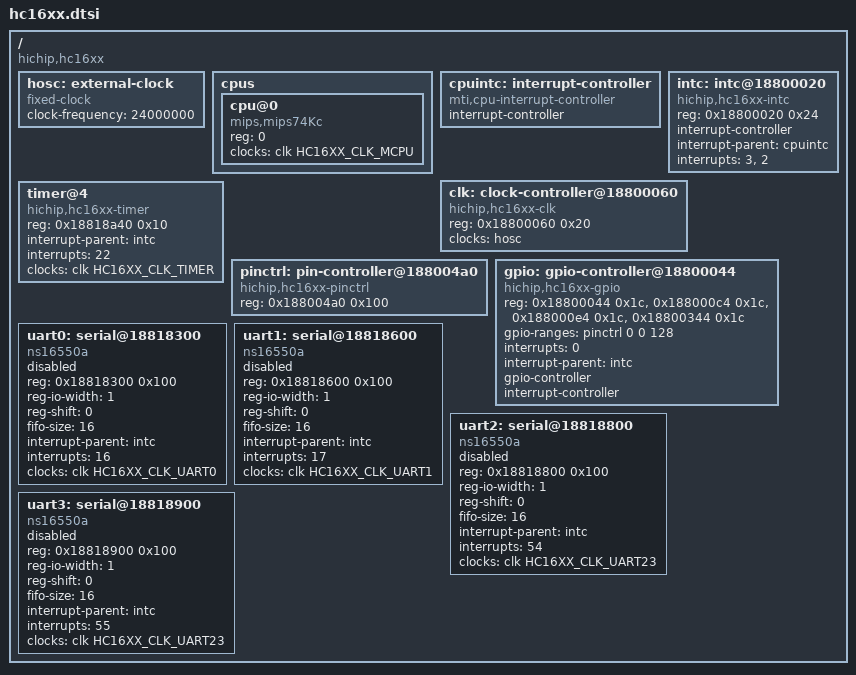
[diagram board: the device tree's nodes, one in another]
// SPDX-License-Identifier: (GPL-2.0-only OR BSD-2-Clause)
/dts-v1/;

#include <dt-bindings/clock/hichip,hc16xx-clock.h>

/ {
	compatible = "hichip,hc16xx";
	#address-cells = <1>;
	#size-cells = <1>;

	hosc: external-clock {
		compatible = "fixed-clock";
		#clock-cells = <0>;
		clock-frequency = <24000000>;  /* 24 MHz, typical */
	};

	cpus: cpus {
		#address-cells = <1>;
		#size-cells = <0>;

		cpu@0 {
			device_type = "cpu";
			compatible = "mips,mips74Kc";
			reg = <0>;

			clocks = <&clk HC16XX_CLK_MCPU>;
			clock-names = "cpu";
		};
	};

	cpuintc: interrupt-controller {
		compatible = "mti,cpu-interrupt-controller";
		interrupt-controller;
		#address-cells = <0>;
		#interrupt-cells = <1>;
	};

	intc: intc@18800020 {
		compatible="hichip,hc16xx-intc";
		reg = <0x18800020 0x24>;

		interrupt-controller;
		#interrupt-cells = <1>;

		interrupt-parent = <&cpuintc>;
		interrupts = <3>, <2>;
	};

	clk: clock-controller@18800060 {
		compatible = "hichip,hc16xx-clk";
		reg = <0x18800060 0x20>;

		clocks = <&hosc>;
		clock-names = "hosc";

		#clock-cells = <1>;
	};

	timer@4 {
		compatible = "hichip,hc16xx-timer";
		reg = <0x18818a40 0x10>;

		interrupt-parent = <&intc>;
		interrupts = <22>;

		clocks = <&clk HC16XX_CLK_TIMER>;
		clock-names = "counting";
	};

	pinctrl: pin-controller@188004a0 {
		compatible = "hichip,hc16xx-pinctrl";
		reg = <0x188004a0 0x100>;
	};

	gpio: gpio-controller@18800044 {
		compatible = "hichip,hc16xx-gpio";
		reg =   <0x18800044 0x1c>, <0x188000c4 0x1c>,
                        <0x188000e4 0x1c>, <0x18800344 0x1c>;
                reg-names = "left", "bottom", "right", "top";
		gpio-ranges = <&pinctrl 0 0 128>;

		interrupts = <0>;
		interrupt-parent=<&intc>;

		gpio-controller;
		#gpio-cells = <2>;

		interrupt-controller;
		#interrupt-cells = <2>;
	};

	uart0: serial@18818300 {
		compatible = "ns16550a";
		reg = <0x18818300 0x100>;
		reg-io-width = <1>;
		reg-shift = <0>;
		fifo-size = <16>;

		interrupt-parent = <&intc>;
		interrupts = <16>;

		clocks = <&clk HC16XX_CLK_UART0>;
		clock-names = "baud";

		status = "disabled";
	};

	uart1: serial@18818600 {
		compatible = "ns16550a";
		reg = <0x18818600 0x100>;
		reg-io-width = <1>;
		reg-shift = <0>;
		fifo-size = <16>;

		interrupt-parent = <&intc>;
		interrupts = <17>;

		clocks = <&clk HC16XX_CLK_UART1>;
		clock-names = "baud";

		status = "disabled";
	};

	uart2: serial@18818800 {
		compatible = "ns16550a";
		reg = <0x18818800 0x100>;
		reg-io-width = <1>;
		reg-shift = <0>;
		fifo-size = <16>;

		interrupt-parent = <&intc>;
		interrupts = <54>;

		clocks = <&clk HC16XX_CLK_UART23>;
		clock-names = "baud";

		status = "disabled";
	};

	uart3: serial@18818900 {
		compatible = "ns16550a";
		reg = <0x18818900 0x100>;
		reg-io-width = <1>;
		reg-shift = <0>;
		fifo-size = <16>;

		interrupt-parent = <&intc>;
		interrupts = <55>;

		clocks = <&clk HC16XX_CLK_UART23>;
		clock-names = "baud";

		status = "disabled";
	};

};
